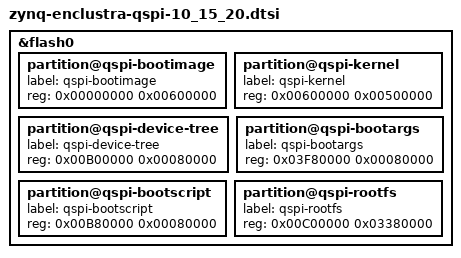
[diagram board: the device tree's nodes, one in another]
&flash0 {
	#address-cells = <1>;
	#size-cells = <1>;
	partition@qspi-bootimage {
		label = "qspi-bootimage";
		reg = <0x00000000 0x00600000>;
	};
	partition@qspi-kernel {
		label = "qspi-kernel";
		reg = <0x00600000 0x00500000>;
	};
	partition@qspi-device-tree {
		label = "qspi-device-tree";
		reg = <0x00B00000 0x00080000>;
	};
	partition@qspi-bootargs {
		label = "qspi-bootargs";
		reg = <0x03F80000 0x00080000>;
	};
	partition@qspi-bootscript {
		label = "qspi-bootscript";
		reg = <0x00B80000 0x00080000>;
	};
	partition@qspi-rootfs {
		label = "qspi-rootfs";
		reg = <0x00C00000 0x03380000>;
	};
};
